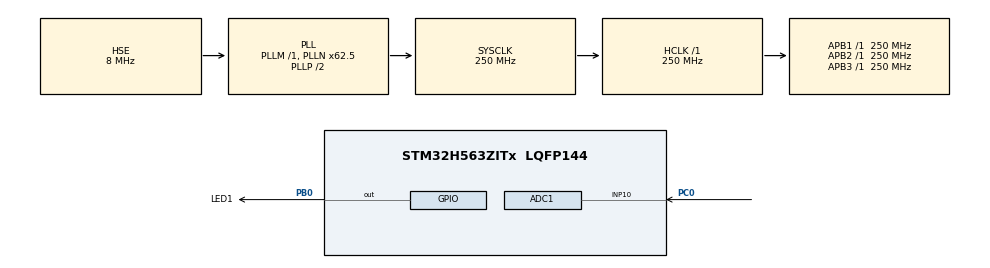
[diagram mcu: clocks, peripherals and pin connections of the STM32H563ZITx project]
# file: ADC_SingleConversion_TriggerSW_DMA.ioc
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ADC1.Channel-0\#ChannelRegularConversion=ADC_CHANNEL_10
ADC1.ClockPrescaler=ADC_CLOCK_SYNC_PCLK_DIV4
ADC1.ContinuousConvMode=DISABLE
ADC1.DMAContinuousRequests=ENABLE
ADC1.NbrOfConversionFlag=1
ADC1.OffsetNumber-0\#ChannelRegularConversion=ADC_OFFSET_NONE
ADC1.Overrun=ADC_OVR_DATA_OVERWRITTEN
ADC1.Rank-0\#ChannelRegularConversion=1
ADC1.SamplingTime-0\#ChannelRegularConversion=ADC_SAMPLETIME_247CYCLES_5
ADC1.master=1
CORTEX_M33_NS.userName=CORTEX_M33
GPDMA1.CIRCULARMODE_GPDMACH1=ENABLE
GPDMA1.DESTDATAWIDTH_GPDMACH1=DMA_DEST_DATAWIDTH_HALFWORD
GPDMA1.DESTINC_GPDMACH1=DMA_DINC_INCREMENTED
GPDMA1.IPHANDLE_GPDMACH1-SIMPLEREQUEST_GPDMACH1=__NULL
GPDMA1.LINKALLOCATEDPORT_CIRCULAR_GPDMACH1=DMA_LINK_ALLOCATED_PORT1
GPDMA1.PRIORITY_LL_CIRCULAR_GPDMACH1=DMA_LOW_PRIORITY_HIGH_WEIGHT
GPDMA1.REQUEST_GPDMACH1=GPDMA1_REQUEST_ADC1
GPDMA1.SRCDATAWIDTH_GPDMACH1=DMA_SRC_DATAWIDTH_HALFWORD
GPDMA1.SRCINC_GPDMACH1=DMA_SINC_FIXED
GPDMA1.TRANSFERALLOCATEDPORTDEST_GPDMACH1=DMA_DEST_ALLOCATED_PORT1
GPDMA1.TRANSFERALLOCATEDPORTSRC_GPDMACH1=DMA_SRC_ALLOCATED_PORT1
Mcu.Family=STM32H5
Mcu.Name=STM32H563ZITx
Mcu.Package=LQFP144
NVIC.ADC1_IRQn=true\:0\:0\:false\:false\:true\:true\:true\:true
NVIC.GPDMA1_Channel1_IRQn=true\:0\:0\:false\:false\:true\:false\:true\:true
NVIC.PriorityGroup=NVIC_PRIORITYGROUP_4
PB0.GPIO_Label=LED1
PB0.Signal=GPIO_Output
PC0.Signal=ADCx_INP10
PH0-OSC_IN(PH0).Mode=HSE-DIG-External-Clock-Source
PH0-OSC_IN(PH0).Signal=RCC_OSC_IN
ProjectManager.HeapSize=0x200
ProjectManager.StackSize=0x400
ProjectManager.TargetToolchain=EWARM V9.20
RCC.ADCCLockSelection=RCC_ADCDACCLKSOURCE_SYSCLK
RCC.ADCFreq_Value=250000000
RCC.AHBFreq_Value=250000000
RCC.APB1Freq_Value=250000000
RCC.APB1TimFreq_Value=250000000
RCC.APB2Freq_Value=250000000
RCC.APB2TimFreq_Value=250000000
RCC.APB3Freq_Value=250000000
RCC.CSI_VALUE=4000000
RCC.CortexFreq_Value=250000000
RCC.EPOD_VALUE=8000000
RCC.HCLKFreq_Value=250000000
RCC.HSE_VALUE=8000000
RCC.HSI48_VALUE=48000000
RCC.HSIDiv=RCC_HSI_DIV1
RCC.HSI_VALUE=64000000
RCC.LSE_VALUE=32768
RCC.LSIRC_VALUE=32000
RCC.PLL2FRACN=4096
RCC.PLL2N=37
RCC.PLLFRACN=4096
RCC.PLLN=62
RCC.PLLSourceVirtual=RCC_PLL1_SOURCE_HSE
RCC.SYSCLKFreq_VALUE=250000000
RCC.SYSCLKSource=RCC_SYSCLKSOURCE_PLLCLK
RCC.USBFreq_Value=48000000
RCC.VCOOutputFreq_Value=500000000
SH.ADCx_INP10.0=ADC1_INP10,IN10-Single-Ended
VP_GPDMA1_VS_GPDMACH1.Mode=SIMPLEREQUEST_GPDMACH1
VP_ICACHE_VS_ICACHE.Mode=DefaultMode
VP_PWR_VS_SECSignals.Mode=Security/Privilege
board=custom

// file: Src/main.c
/* USER CODE BEGIN Header */
/**
  ******************************************************************************
  * @file    Examples/ADC/ADC_SingleConversion_TriggerSW_DMA/Src/main.c
  * @author  MCD Application Team
  * @brief   This example describes how to use a ADC peripheral to perform
  *          a single ADC conversion of a channel, at each software start.
  *          Conversion data is transferred by DMA into a table in RAM memory,
  *          indefinitely (circular mode).
  *          This example is based on the STM32H5xx ADC HAL API.
  ******************************************************************************
  * @attention
  *
  * Copyright (c) 2023 STMicroelectronics.
  * All rights reserved.
  *
  * This software is licensed under terms that can be found in the LICENSE file
  * in the root directory of this software component.
  * If no LICENSE file comes with this software, it is provided AS-IS.
  *
  ******************************************************************************
  */
/* USER CODE END Header */
#include "main.h"

/* USER CODE BEGIN PD */

/* Definitions of environment analog values */
  /* Value of analog reference voltage (Vref+), connected to analog voltage   */
  /* supply Vdda (unit: mV).                                                  */
  #define VDDA_APPLI                       (3300UL)

/* Definitions of data related to this example */
  /* Definition of ADCx conversions data table size */
  #define ADC_CONVERTED_DATA_BUFFER_SIZE   (   4UL)

  /* Init variable out of expected ADC conversion data range */
  #define VAR_CONVERTED_DATA_INIT_VALUE    (__LL_ADC_DIGITAL_SCALE(LL_ADC_RESOLUTION_12B) + 1)

/* USER CODE END PD */

ADC_HandleTypeDef hadc1;
DMA_NodeTypeDef Node_GPDMA1_Channel1;
DMA_QListTypeDef List_GPDMA1_Channel1;
DMA_HandleTypeDef handle_GPDMA1_Channel1;

/* USER CODE BEGIN PV */

/* Variables for ADC conversion data */
__IO uint16_t uhADCxConvertedData[ADC_CONVERTED_DATA_BUFFER_SIZE]; /* ADC group regular conversion data (array of data) */

/* Variables for ADC conversion data computation to physical values */
uint16_t uhADCxConvertedData_Voltage_mVolt[ADC_CONVERTED_DATA_BUFFER_SIZE];  /* Value of voltage calculated from ADC conversion data (unit: mV) (array of data) */

/* Variable to report status of DMA transfer of ADC group regular conversions */
/*  0: DMA transfer is not completed                                          */
/*  1: DMA transfer is completed                                              */
/*  2: DMA transfer has not yet been started yet (initial state)              */
__IO uint8_t ubDmaTransferStatus = 2U; /* Variable set into DMA interruption callback */

/* USER CODE END PV */

void SystemClock_Config(void);
static void MX_GPIO_Init(void);
static void MX_GPDMA1_Init(void);
static void MX_ICACHE_Init(void);
static void MX_ADC1_Init(void);

int main(void)
{

  /* USER CODE BEGIN 1 */
  uint32_t tmp_index;

  /* Initialize ADC group regular data buffer values */
  for (tmp_index = 0; tmp_index < ADC_CONVERTED_DATA_BUFFER_SIZE; tmp_index++)
  {
    uhADCxConvertedData[tmp_index] = VAR_CONVERTED_DATA_INIT_VALUE;
  }

  /* USER CODE END 1 */

  /* MCU Configuration--------------------------------------------------------*/

  /* Reset of all peripherals, Initializes the Flash interface and the Systick. */
  HAL_Init();

  /* Configure the system clock */
  SystemClock_Config();

  /* Initialize all configured peripherals */
  MX_GPIO_Init();
  MX_GPDMA1_Init();
  MX_ICACHE_Init();
  MX_ADC1_Init();
  /* USER CODE BEGIN 2 */

  /* Initialize LED on board */
  BSP_LED_Init(LED1);

  /* Perform ADC calibration */
  if (HAL_ADCEx_Calibration_Start(&hadc1, ADC_SINGLE_ENDED) != HAL_OK)
  {
    /* Calibration Error */
    Error_Handler();
  }

  /* Start ADC group regular conversion */
  /* Note: First start with DMA transfer initialization, following ones
           with basic ADC start. */
  if (HAL_ADC_Start_DMA(&hadc1,
                        (uint32_t *)uhADCxConvertedData,
                        ADC_CONVERTED_DATA_BUFFER_SIZE
                       ) != HAL_OK)
  {
    /* Error: ADC conversion start could not be performed */
    Error_Handler();
  }

  /* Toggle LED at each ADC conversion */
  BSP_LED_On(LED1);
  HAL_Delay(LED_BLINK_SLOW);
  BSP_LED_Off(LED1);
  HAL_Delay(LED_BLINK_SLOW);

  /* USER CODE END 2 */

  /* Infinite loop */
  /* USER CODE BEGIN WHILE */
  while (1)
  {
    /* Start ADC group regular conversion */
    if (HAL_ADC_Start(&hadc1) != HAL_OK)
    {
      /* Error: ADC conversion start could not be performed */
      Error_Handler();
    }

    /* Toggle LED at each ADC conversion */
    BSP_LED_On(LED1);
    HAL_Delay(LED_BLINK_SLOW);
    BSP_LED_Off(LED1);
    HAL_Delay(LED_BLINK_SLOW);

    /* Note: ADC group regular conversions data are stored into array         */
    /*       "uhADCxConvertedData"                                            */
    /*       (for debug: see variable content into watch window).             */

    /* Note: ADC conversion data are computed to physical values              */
    /*       into array "uhADCxConvertedData_Voltage_mVolt" using             */
    /*       ADC LL driver helper macro "__LL_ADC_CALC_DATA_TO_VOLTAGE()"     */
    /*       (for debug: see variable content with debugger)                  */

    /* If ADC conversions and DMA transfer are completed, then process data */
    if(ubDmaTransferStatus == 1)
    {
      /* Update status variable of DMA transfer */
      ubDmaTransferStatus = 0;

      /* Computation of ADC conversions raw data to physical values
         using LL ADC driver helper macro. */
      for (tmp_index = 0; tmp_index < ADC_CONVERTED_DATA_BUFFER_SIZE; tmp_index++)
      {
        uhADCxConvertedData_Voltage_mVolt[tmp_index] = __LL_ADC_CALC_DATA_TO_VOLTAGE(VDDA_APPLI, uhADCxConvertedData[tmp_index], LL_ADC_RESOLUTION_12B);
      }

      /* Toggle LED 4 times */
      tmp_index = 4*2;
      while(tmp_index != 0)
      {
        BSP_LED_Toggle(LED1);
        HAL_Delay(LED_BLINK_FAST);
        tmp_index--;
      }
      HAL_Delay(500); /* Delay to highlight toggle sequence */
    }

    /* USER CODE END WHILE */

  }
}

void SystemClock_Config(void)
{
  RCC_OscInitTypeDef RCC_OscInitStruct = {0};
  RCC_ClkInitTypeDef RCC_ClkInitStruct = {0};

  /** Configure the main internal regulator output voltage
  */
  __HAL_PWR_VOLTAGESCALING_CONFIG(PWR_REGULATOR_VOLTAGE_SCALE0);

  while(!__HAL_PWR_GET_FLAG(PWR_FLAG_VOSRDY)) {}

  /** Initializes the RCC Oscillators according to the specified parameters
  * in the RCC_OscInitTypeDef structure.
  */
  RCC_OscInitStruct.OscillatorType = RCC_OSCILLATORTYPE_HSE;
  RCC_OscInitStruct.HSEState = RCC_HSE_BYPASS_DIGITAL;
  RCC_OscInitStruct.PLL.PLLState = RCC_PLL_ON;
  RCC_OscInitStruct.PLL.PLLSource = RCC_PLL1_SOURCE_HSE;
  RCC_OscInitStruct.PLL.PLLM = 1;
  RCC_OscInitStruct.PLL.PLLN = 62;
  RCC_OscInitStruct.PLL.PLLP = 2;
  RCC_OscInitStruct.PLL.PLLQ = 2;
  RCC_OscInitStruct.PLL.PLLR = 2;
  RCC_OscInitStruct.PLL.PLLRGE = RCC_PLL1_VCIRANGE_3;
  RCC_OscInitStruct.PLL.PLLVCOSEL = RCC_PLL1_VCORANGE_WIDE;
  RCC_OscInitStruct.PLL.PLLFRACN = 4096;
  if (HAL_RCC_OscConfig(&RCC_OscInitStruct) != HAL_OK)
  {
    Error_Handler();
  }

  /** Initializes the CPU, AHB and APB buses clocks
  */
  RCC_ClkInitStruct.ClockType = RCC_CLOCKTYPE_HCLK|RCC_CLOCKTYPE_SYSCLK
                              |RCC_CLOCKTYPE_PCLK1|RCC_CLOCKTYPE_PCLK2
                              |RCC_CLOCKTYPE_PCLK3;
  RCC_ClkInitStruct.SYSCLKSource = RCC_SYSCLKSOURCE_PLLCLK;
  RCC_ClkInitStruct.AHBCLKDivider = RCC_SYSCLK_DIV1;
  RCC_ClkInitStruct.APB1CLKDivider = RCC_HCLK_DIV1;
  RCC_ClkInitStruct.APB2CLKDivider = RCC_HCLK_DIV1;
  RCC_ClkInitStruct.APB3CLKDivider = RCC_HCLK_DIV1;

  if (HAL_RCC_ClockConfig(&RCC_ClkInitStruct, FLASH_LATENCY_5) != HAL_OK)
  {
    Error_Handler();
  }

  /** Configure the programming delay
  */
  __HAL_FLASH_SET_PROGRAM_DELAY(FLASH_PROGRAMMING_DELAY_2);
}

static void MX_ADC1_Init(void)
{

  ADC_ChannelConfTypeDef sConfig = {0};

  /** Common config
  */
  hadc1.Instance = ADC1;
  hadc1.Init.ClockPrescaler = ADC_CLOCK_SYNC_PCLK_DIV4;
  hadc1.Init.Resolution = ADC_RESOLUTION_12B;
  hadc1.Init.DataAlign = ADC_DATAALIGN_RIGHT;
  hadc1.Init.ScanConvMode = ADC_SCAN_DISABLE;
  hadc1.Init.EOCSelection = ADC_EOC_SINGLE_CONV;
  hadc1.Init.LowPowerAutoWait = DISABLE;
  hadc1.Init.ContinuousConvMode = DISABLE;
  hadc1.Init.NbrOfConversion = 1;
  hadc1.Init.DiscontinuousConvMode = DISABLE;
  hadc1.Init.ExternalTrigConv = ADC_SOFTWARE_START;
  hadc1.Init.ExternalTrigConvEdge = ADC_EXTERNALTRIGCONVEDGE_NONE;
  hadc1.Init.DMAContinuousRequests = ENABLE;
  hadc1.Init.SamplingMode = ADC_SAMPLING_MODE_NORMAL;
  hadc1.Init.Overrun = ADC_OVR_DATA_OVERWRITTEN;
  hadc1.Init.OversamplingMode = DISABLE;
  if (HAL_ADC_Init(&hadc1) != HAL_OK)
  {
    Error_Handler();
  }

  /** Configure Regular Channel
  */
  sConfig.Channel = ADC_CHANNEL_10;
  sConfig.Rank = ADC_REGULAR_RANK_1;
  sConfig.SamplingTime = ADC_SAMPLETIME_247CYCLES_5;
  sConfig.SingleDiff = ADC_SINGLE_ENDED;
  sConfig.OffsetNumber = ADC_OFFSET_NONE;
  sConfig.Offset = 0;
  if (HAL_ADC_ConfigChannel(&hadc1, &sConfig) != HAL_OK)
  {
    Error_Handler();
  }

}

static void MX_GPDMA1_Init(void)
{

  /* Peripheral clock enable */
  __HAL_RCC_GPDMA1_CLK_ENABLE();

  /* GPDMA1 interrupt Init */
    HAL_NVIC_SetPriority(GPDMA1_Channel1_IRQn, 0, 0);
    HAL_NVIC_EnableIRQ(GPDMA1_Channel1_IRQn);

}

static void MX_ICACHE_Init(void)
{

  /** Enable instruction cache (default 2-ways set associative cache)
  */
  if (HAL_ICACHE_Enable() != HAL_OK)
  {
    Error_Handler();
  }

}

static void MX_GPIO_Init(void)
{
  GPIO_InitTypeDef GPIO_InitStruct = {0};

  /* GPIO Ports Clock Enable */
  __HAL_RCC_GPIOH_CLK_ENABLE();
  __HAL_RCC_GPIOC_CLK_ENABLE();
  __HAL_RCC_GPIOB_CLK_ENABLE();

  /*Configure GPIO pin Output Level */
  HAL_GPIO_WritePin(LED1_GPIO_Port, LED1_Pin, GPIO_PIN_RESET);

  /*Configure GPIO pin : LED1_Pin */
  GPIO_InitStruct.Pin = LED1_Pin;
  GPIO_InitStruct.Mode = GPIO_MODE_OUTPUT_PP;
  GPIO_InitStruct.Pull = GPIO_NOPULL;
  GPIO_InitStruct.Speed = GPIO_SPEED_FREQ_LOW;
  HAL_GPIO_Init(LED1_GPIO_Port, &GPIO_InitStruct);

}

/* USER CODE BEGIN 4 */

/******************************************************************************/
/*   USER IRQ HANDLER TREATMENT                                               */
/******************************************************************************/

/**
  * @brief  DMA transfer complete callback
  * @note   This function is executed when the transfer complete interrupt
  *         is generated
  * @retval None
  */
void HAL_ADC_ConvCpltCallback(ADC_HandleTypeDef *hadc)
{
  /* Update status variable of DMA transfer */
  ubDmaTransferStatus = 1;
}

/**
  * @brief  ADC error interruption callback
  * @retval None
  */
void HAL_ADC_ErrorCallback(ADC_HandleTypeDef *hadc)
{
  /* Note: Disable ADC interruption that caused this error before entering in
           infinite loop below. */

  /* In case of error due to overrun: Disable ADC group regular overrun interruption */
  LL_ADC_DisableIT_OVR(ADC1);

  /* Error reporting */
  Error_Handler();
}

/* USER CODE END 4 */

void Error_Handler(void)
{
  /* USER CODE BEGIN Error_Handler_Debug */
  /* User can add his own implementation to report the HAL error return state */

  /* Turn on LED and remain in infinite loop */
  while (1)
  {
    BSP_LED_On(LED1);
  }
  /* USER CODE END Error_Handler_Debug */
}
